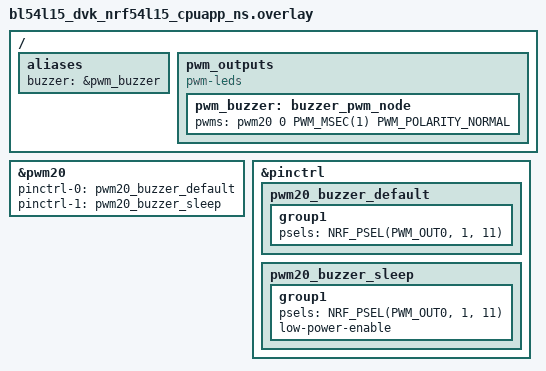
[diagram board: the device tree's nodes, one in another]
/ {
	aliases {
		buzzer = &pwm_buzzer;
	};

	pwm_outputs {
		compatible = "pwm-leds";
		pwm_buzzer: buzzer_pwm_node {
			pwms = <&pwm20 0 PWM_MSEC(1) PWM_POLARITY_NORMAL>;
		};
	};
};

&pwm20 {
	status = "okay";
	pinctrl-0 = <&pwm20_buzzer_default>;
	pinctrl-1 = <&pwm20_buzzer_sleep>;
	pinctrl-names = "default", "sleep";
};

&pinctrl {
	pwm20_buzzer_default: pwm20_buzzer_default {
		group1 {
			psels = <NRF_PSEL(PWM_OUT0, 1, 11)>;
		};
	};

	pwm20_buzzer_sleep: pwm20_buzzer_sleep {
		group1 {
			psels = <NRF_PSEL(PWM_OUT0, 1, 11)>;
			low-power-enable;
		};
	};
};
